# TMS320F280049 register map
Vendor: Texas Instruments; Series: C2000 F28004x; File version: 0.2.0-generated
Registers are 16-bit, read-write, reset 0x0 unless marked. A register's access mark holds for its fields unless they carry their own. Offsets are from the block's base; [hi:lo] are bit positions.

## PMBUSAREGS — PMBUS Registers
Base 0x0000C800
0x00 PMBMC 32-bit — PMBUS Master Mode Control Register
  [20] PRC_CALL — Master Process Call Message Enable
  [19] GRP_CMD — Master Group Command Message Enable
  [18] PEC_ENA — Master PEC Processing Enable
  [17] EXT_CMD — Master Extended Command Code Enable
  [16] CMD_ENA — Master Command Code Enable
  [22:15] BYTE_COUNT — Number of Bytes Transmitted
  [13:7] SLAVE_ADDR — Slave Address
  [0] RW — RnW bit of the Message
0x04 PMBTXBUF 32-bit — PMBUS Transmit Buffer
  [31] TXDATA — Transmit Message Data
0x08 PMBRXBUF 32-bit — PMBUS Receive buffer
  [31] RXDATA — PMBus Receive Data Register
0x0C PMBACK 32-bit — PMBUS Acknowledge Register
  [0] ACK — Allows firmware to ack/nack received data
0x10 PMBSTS 32-bit — PMBUS Status Register
  [21] SCL_RAW — PMBus Clock Pin Real Time Status
  [20] SDA_RAW — PMBus Data Pin Real Time Status
  [19] CONTROL_RAW — Control Pin Real Time Status
  [18] ALERT_RAW — Alert Pin Real Time Status
  [17] CONTROL_EDGE — Control Edge Detection Status
  [16] ALERT_EDGE — Alert Edge Detection Status
  [15] MASTER — Master Indicator
  [14] LOST_ARB — Lost Arbitration Flag
  [13] BUS_FREE — PMBus Free Indicator
  [12] UNIT_BUSY — PMBus Busy Indicator
  [11] RPT_START — Repeated Start Flag
  [10] SLAVE_ADDR_READY — Slave Address Ready
  [9] CLK_HIGH_DETECTED — Clock High Detection Status
  [8] CLK_LOW_TIMEOUT — Clock Low Timeout Status
  [7] PEC_VALID — PEC Valid Indicator
  [6] NACK — Not Acknowledge Flag Status
  [5] EOM — End of Message Indicator
  [4] DATA_REQUEST — Data Request Flag
  [3] DATA_READY — Data Ready Flag
  [4:2] RD_BYTE_COUNT — Number of Data Bytes available in Receive Data Register
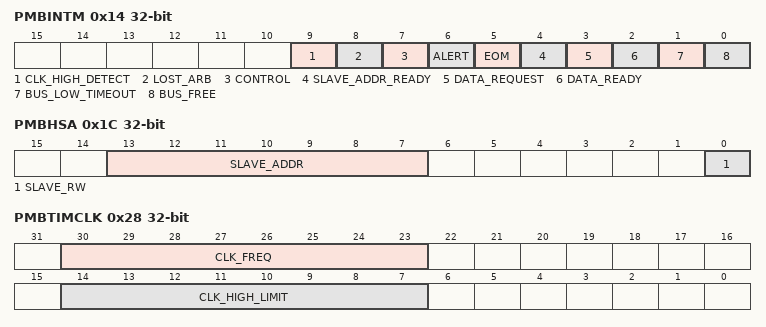
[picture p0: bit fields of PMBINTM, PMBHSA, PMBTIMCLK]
0x14 PMBINTM 32-bit — PMBUS Interrupt Mask Register
  [9] CLK_HIGH_DETECT — Clock High Detection Interrupt Mask
  [8] LOST_ARB — Lost Arbitration Interrupt Mask
  [7] CONTROL — Control Detection Interrupt Mask
  [6] ALERT — Alert Detection Interrupt Mask
  [5] EOM — End of Message Interrupt Mask
  [4] SLAVE_ADDR_READY — Slave Address Ready Interrupt Mask
  [3] DATA_REQUEST — Data Request Interrupt Mask
  [2] DATA_READY — Data Ready Interrupt Mask
  [1] BUS_LOW_TIMEOUT — Clock Low Timeout Interrupt Mask
  [0] BUS_FREE — Bus Free Interrupt Mask
0x18 PMBSC 32-bit — PMBUS Slave Mode Configuration Register
  [23:22] RX_BYTE_ACK_CNT — Number of data bytes to automatically acknowledge
  [20] MAN_CMD — Manual Command Acknowledgement Mode
  [19] TX_PEC — send a PEC byte at end of message
  [20:18] TX_COUNT — Number of valid bytes in Transmit Data Register
  [15] PEC_ENA — PEC Processing Enable
  [20:14] SLAVE_MASK — Slave address mask
  [7] MAN_SLAVE_ACK — Manual Slave Address Acknowledgement Mode
  [12:6] SLAVE_ADDR — Configures the current device address of the slave.
0x1C PMBHSA 32-bit — PMBUS Hold Slave Address Register
  [13:7] SLAVE_ADDR — Stored device address
  [0] SLAVE_RW — Stored R/W bit
0x20 PMBCTRL 32-bit — PMBUS Control Register
  [31] I2CMODE — Bit to enable I2C mode
  [31:27] CLKDIV — PMBUS Clock Divide Value
  [22] MASTER_EN — PMBus Master Enable
  [21] SLAVE_EN — PMBus Slave Enable
  [20] CLK_LO_DIS — Clock Low Timeout Disable
  [17] SCL_DIR — Configures direction of PMBus clock pin in GPIO mode
  [16] SCL_VALUE — Configures output value of PMBus clock pin in GPIO Mode
  [15] SCL_MODE — Configures mode of PMBus Clock pin
  [14] SDA_DIR — Configures direction of PMBus data pin in GPIO mode
  [13] SDA_VALUE — Configures output value of PMBus data pin in GPIO Mode
  [12] SDA_MODE — Configures mode of PMBus Data pin
  [11] CNTL_DIR — Configures direction of Control pin in GPIO mode
  [10] CNTL_VALUE — Configures output value of Control pin in GPIO Mode
  [9] CNTL_MODE — Configures mode of Control pin
  [8] ALERT_DIR — Configures direction of Alert pin in GPIO mode
  [7] ALERT_VALUE — Configures output value of Alert pin in GPIO Mode
  [6] ALERT_MODE — Configures mode of Alert pin
  [5] CNTL_INT_EDGE — Control Interrupt Edge Select
  [3] FAST_MODE — Fast Mode Enable
  [2] BUS_LO_INT_EDGE — Clock Low Timeout Interrupt Edge Select
  [1] ALERT_EN — Slave Alert Enable
  [0] RESET — PMBus Interface Synchronous Reset
0x24 PMBTIMCTL 32-bit — PMBUS Timing Control Register
  [0] TIM_OVERRIDE — Overide the default settings of the timing parameters.
0x28 PMBTIMCLK 32-bit — PMBUS Clock Timing Register
  [30:23] CLK_FREQ — Determines the PMBUS master clock frequency.
  [14:7] CLK_HIGH_LIMIT — Determines the PMBUS master clock high pulse width.
0x2C PMBTIMSTSETUP 32-bit — PMBUS Start Setup Time Register
  [14:7] TSU_STA — Setup time, rise edge of PMBUS master clock to start edge.
0x30 PMBTIMBIDLE 32-bit — PMBUS Bus Idle Time Register
  [18:9] BUSIDLE — Determines the Bus Idle Limit
0x34 PMBTIMLOWTIMOUT 32-bit — PMBUS Clock Low Timeout Value Register
  [31:19] CLKLOWTIMOUT — Determines the clock low timeout value
0x38 PMBTIMHIGHTIMOUT 32-bit — PMBUS Clock High Timeout Value Register
  [18:9] CLKHIGHTIMOUT — Determines the clock high timeout value
